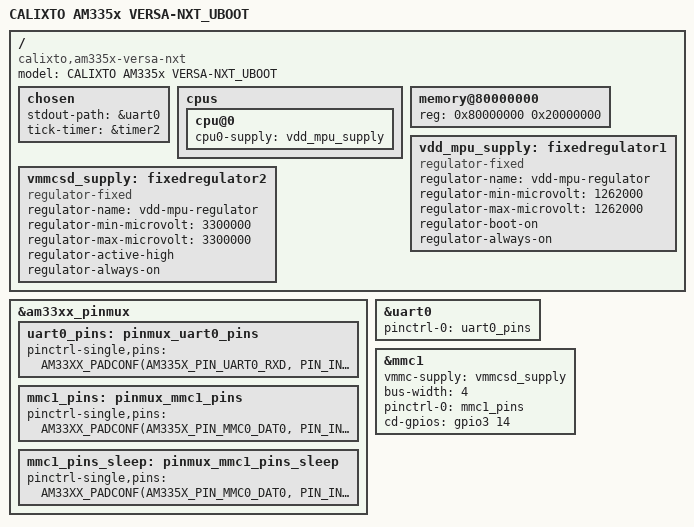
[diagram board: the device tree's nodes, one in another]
/*
 * Copyright (C) 2012 Texas Instruments Incorporated - http://www.ti.com/
 *
 * This program is free software; you can redistribute it and/or modify
 * it under the terms of the GNU General Public License version 2 as
 * published by the Free Software Foundation.
 */
/dts-v1/;

#include "am33xx.dtsi"
#include <dt-bindings/interrupt-controller/irq.h>
/ {
	model = "CALIXTO AM335x VERSA-NXT_UBOOT";
	compatible = "calixto,am335x-versa-nxt", "ti,am335x", "ti,am33xx";

	chosen {
		stdout-path = &uart0;
		tick-timer = &timer2;
	};

	cpus {
		cpu@0 {
			cpu0-supply = <&vdd_mpu_supply>;
		};
	};

	memory@80000000 {
		device_type = "memory";
		reg = <0x80000000 0x20000000>; /* 512 MB */
	};
	
	vdd_mpu_supply: fixedregulator1 {
		compatible = "regulator-fixed";
		regulator-name = "vdd-mpu-regulator";
		regulator-min-microvolt = <1262000>;
		regulator-max-microvolt = <1262000>;
		regulator-boot-on;
		regulator-always-on;
	};
	
	vmmcsd_supply: fixedregulator2 {
		compatible = "regulator-fixed";
		regulator-name = "vdd-mpu-regulator";
		regulator-min-microvolt = <3300000>;
		regulator-max-microvolt = <3300000>;
		regulator-active-high;
		regulator-always-on;
	};

};

&am33xx_pinmux {
	pinctrl-names = "default";


	uart0_pins: pinmux_uart0_pins {
		pinctrl-single,pins = <
			AM33XX_PADCONF(AM335X_PIN_UART0_RXD, PIN_INPUT_PULLUP, MUX_MODE0)
			AM33XX_PADCONF(AM335X_PIN_UART0_TXD, PIN_OUTPUT_PULLDOWN, MUX_MODE0)
		>;
	};

        mmc1_pins: pinmux_mmc1_pins {
                pinctrl-single,pins = <
                        AM33XX_PADCONF(AM335X_PIN_MMC0_DAT0, PIN_INPUT_PULLUP, MUX_MODE0)
			AM33XX_PADCONF(AM335X_PIN_MMC0_DAT1, PIN_INPUT_PULLUP, MUX_MODE0)
			AM33XX_PADCONF(AM335X_PIN_MMC0_DAT2, PIN_INPUT_PULLUP, MUX_MODE0)
			AM33XX_PADCONF(AM335X_PIN_MMC0_DAT3, PIN_INPUT_PULLUP, MUX_MODE0)
			AM33XX_PADCONF(AM335X_PIN_MMC0_CMD, PIN_INPUT_PULLUP, MUX_MODE0)
			AM33XX_PADCONF(AM335X_PIN_MMC0_CLK, PIN_INPUT_PULLUP, MUX_MODE0)
                        AM33XX_PADCONF(AM335X_PIN_MCASP0_ACLKX, PIN_INPUT, MUX_MODE7)           /* mcasp0_aclkx.gpio3_14 */
                >;
        };

	mmc1_pins_sleep: pinmux_mmc1_pins_sleep {
                pinctrl-single,pins = <
                        AM33XX_PADCONF(AM335X_PIN_MMC0_DAT0, PIN_INPUT_PULLDOWN, MUX_MODE7)
			AM33XX_PADCONF(AM335X_PIN_MMC0_DAT1, PIN_INPUT_PULLDOWN, MUX_MODE7)
			AM33XX_PADCONF(AM335X_PIN_MMC0_DAT2, PIN_INPUT_PULLDOWN, MUX_MODE7)
			AM33XX_PADCONF(AM335X_PIN_MMC0_DAT3, PIN_INPUT_PULLDOWN, MUX_MODE7)
			AM33XX_PADCONF(AM335X_PIN_MMC0_CMD, PIN_INPUT_PULLDOWN, MUX_MODE7)
			AM33XX_PADCONF(AM335X_PIN_MMC0_CLK, PIN_INPUT_PULLDOWN, MUX_MODE7)
                        AM33XX_PADCONF(AM335X_PIN_MCASP0_ACLKX, PIN_INPUT, MUX_MODE7)           /* mcasp0_aclkx.gpio3_14 */
                >;
        };

};

&uart0 {
	pinctrl-names = "default";
	pinctrl-0 = <&uart0_pins>;

	status = "okay";
};

&mmc1 {
	status = "okay";
	vmmc-supply = <&vmmcsd_supply>;
	bus-width = <4>;
	pinctrl-names = "default";
	pinctrl-0 = <&mmc1_pins>;
	cd-gpios = <&gpio3 14 GPIO_ACTIVE_HIGH>;
};
